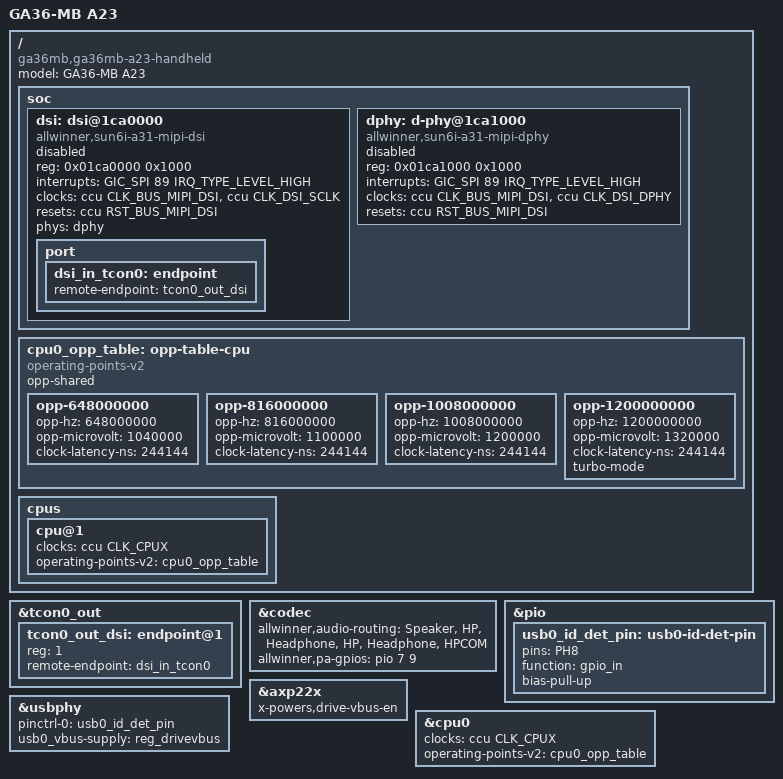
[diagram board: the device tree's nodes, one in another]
#include "sun8i-a23.dtsi"

/ {
    model = "GA36-MB A23";
    compatible = "ga36mb,ga36mb-a23-handheld",
    "allwinner,sun8i-a23";

    soc {
		dsi: dsi@1ca0000 {
			compatible = "allwinner,sun6i-a31-mipi-dsi";
			reg = <0x01ca0000 0x1000>;
			interrupts = <GIC_SPI 89 IRQ_TYPE_LEVEL_HIGH>;
			clocks = <&ccu CLK_BUS_MIPI_DSI>, <&ccu CLK_DSI_SCLK>;
			clock-names = "bus", "mod";
			resets = <&ccu RST_BUS_MIPI_DSI>;
			phys = <&dphy>;
			phy-names = "dphy";
			status = "disabled";
			#address-cells = <1>;
			#size-cells = <0>;

			port {
				dsi_in_tcon0: endpoint {
					remote-endpoint = <&tcon0_out_dsi>;
				};
			};
		};
		dphy: d-phy@1ca1000 {
			compatible = "allwinner,sun6i-a31-mipi-dphy";
			reg = <0x01ca1000 0x1000>;
			interrupts = <GIC_SPI 89 IRQ_TYPE_LEVEL_HIGH>;
			clocks = <&ccu CLK_BUS_MIPI_DSI>, <&ccu CLK_DSI_DPHY>;
			clock-names = "bus", "mod";
			resets = <&ccu RST_BUS_MIPI_DSI>;
			status = "disabled";
			#phy-cells = <0>;
		};
    };
};

#include "ga36mb.dtsi"

&tcon0_out {
	#address-cells = <1>;
	#size-cells = <0>;

	tcon0_out_dsi: endpoint@1 {
		reg = <1>;
		remote-endpoint = <&dsi_in_tcon0>;
	};
};

&codec {
    allwinner,audio-routing = "Speaker", "HP",
        "Headphone", "HP",
        "Headphone", "HPCOM";	/* direct drive: the jack's return is HPCOM */
    allwinner,pa-gpios = <&pio 7 9 GPIO_ACTIVE_HIGH>; /* PH09 */
};

&pio {
    usb0_id_det_pin: usb0-id-det-pin {
        pins = "PH8";
        function = "gpio_in";
        bias-pull-up;
    };
};

&axp22x {
    x-powers,drive-vbus-en;	/* registers reg_drivevbus; without it usbphy defers forever and musb never probes */
};

&usbphy {
    pinctrl-names = "default";
    pinctrl-0 = <&usb0_id_det_pin>;
    usb0_vbus-supply = <&reg_drivevbus>;
};

/*
 * FakeR36S-OS: CPU frequency scaling for the A23.
 * Mainline sun8i-a23.dtsi has no OPP table, so the CPU stays at the
 * bootloader's 1008 MHz forever. These points are copied from this board's
 * own stock script.bin [dvfs_table] (GA36-MB A23 Esisla), so no voltage is
 * ever higher than what the vendor firmware uses:
 *   648 MHz @ 1.04 V, 816 MHz @ 1.10 V, 1008 MHz @ 1.20 V (stock boot clock)
 *   1200 MHz @ 1.32 V = vendor max_freq, marked turbo-mode: only used when
 *   boost is switched on (/sys/devices/system/cpu/cpufreq/boost = 1).
 * The vendor's 1344/1536 MHz "extremity" points are deliberately left out.
 */
/ {
	cpu0_opp_table: opp-table-cpu {
		compatible = "operating-points-v2";
		opp-shared;

		opp-648000000 {
			opp-hz = /bits/ 64 <648000000>;
			opp-microvolt = <1040000>;
			clock-latency-ns = <244144>; /* 8 32k periods */
		};

		opp-816000000 {
			opp-hz = /bits/ 64 <816000000>;
			opp-microvolt = <1100000>;
			clock-latency-ns = <244144>;
		};

		opp-1008000000 {
			opp-hz = /bits/ 64 <1008000000>;
			opp-microvolt = <1200000>;
			clock-latency-ns = <244144>;
		};

		opp-1200000000 {
			opp-hz = /bits/ 64 <1200000000>;
			opp-microvolt = <1320000>;
			clock-latency-ns = <244144>;
			turbo-mode;
		};
	};

	cpus {
		cpu@1 {
			clocks = <&ccu CLK_CPUX>;
			clock-names = "cpu";
			operating-points-v2 = <&cpu0_opp_table>;
		};
	};
};

&cpu0 {
	clocks = <&ccu CLK_CPUX>;
	clock-names = "cpu";
	operating-points-v2 = <&cpu0_opp_table>;
};
